# S3C2440A register map
Vendor: Samsung; Series: S3C2440; File version: 1.0
CPU: ARM920T r1p1, little endian, MPU, no FPU, 0 interrupt priority bits
Registers are 32-bit, read-write, reset 0x0 unless marked. A register's access mark holds for its fields unless they carry their own. Offsets are from the block's base; [hi:lo] are bit positions; {n}, {i} and the like mark numbered series.

## CLKPWR — Clock & Power Management
Base 0x4C000000
0x00 LOCKTIME reset 0xFFFFFF — PLL Lock Time Counter
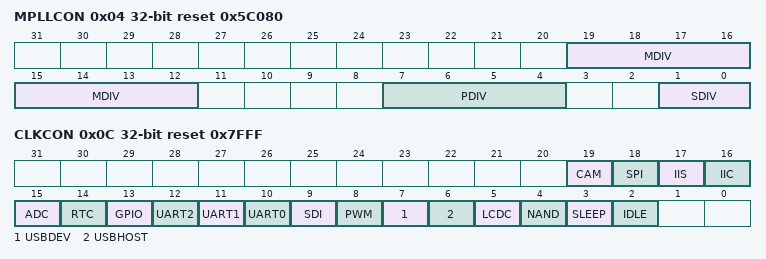
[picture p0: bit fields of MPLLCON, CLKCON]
0x04 MPLLCON reset 0x5C080 — MPLL Control Register
  [19:12] MDIV — Main Divider
  [7:4] PDIV — Pre-divider
  [1:0] SDIV — Post-divider
0x08 UPLLCON reset 0x28080 — UPLL Control Register
0x0C CLKCON reset 0x7FFF — Clock Control Register
  [19] CAM — Camera interface clock enable
  [18] SPI — SPI clock enable
  [17] IIS — IIS clock enable
  [16] IIC — IIC clock enable
  [15] ADC — ADC clock enable
  [14] RTC — RTC clock enable
  [13] GPIO — GPIO clock enable
  [12] UART2 — UART2 clock enable
  [11] UART1 — UART1 clock enable
  [10] UART0 — UART0 clock enable
  [9] SDI — SDI clock enable
  [8] PWM — PWM timer clock enable
  [7] USBDEV — USB device clock enable
  [6] USBHOST — USB host clock enable
  [5] LCDC — LCD controller clock enable
  [4] NAND — NAND Flash controller clock enable
  [3] SLEEP — Sleep mode
  [2] IDLE — Idle mode
0x10 CLKSLOW — Slow Clock Control Register
0x14 CLKDIVN — Clock Divider Control Register

## LCDC — LCD Controller
Base 0x4D000000
0x00 LCDCON1 — LCD Control 1 Register
0x04 LCDCON2 — LCD Control 2 Register
0x08 LCDCON3 — LCD Control 3 Register
0x0C LCDCON4 — LCD Control 4 Register
0x10 LCDCON5 — LCD Control 5 Register
0x14 LCDSADDR1 — Frame Buffer Start Address 1
0x18 LCDSADDR2 — Frame Buffer Start Address 2
0x1C LCDSADDR3 — Virtual Screen Address Set

## NFCON — NAND Flash Controller
Base 0x4E000000
0x00 NFCONF — NAND Flash Configuration
0x04 NFCMD 8-bit wo — NAND Flash Command
0x08 NFADDR 8-bit wo — NAND Flash Address
0x0C NFDATA 8-bit — NAND Flash Data
0x10 NFSTAT 8-bit ro — NAND Flash Status

## UART0
Base 0x50000000
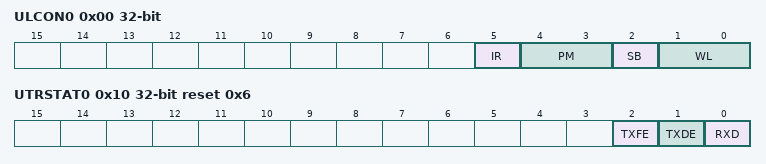
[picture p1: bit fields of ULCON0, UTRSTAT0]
0x00 ULCON0 — UART Line Control Register 0
  [5] IR — Infrared Mode (0=normal, 1=infrared)
  [4:3] PM — Parity Mode (00=no parity, 01=odd, 10=even, 11=parity forced/check)
  [2] SB — Stop Bits (0=1 bit, 1=2 bits)
  [1:0] WL — Word Length (00=5-bit, 01=6-bit, 10=7-bit, 11=8-bit)
0x04 UCON0 — UART Control Register 0
0x08 UFCON0 — UART FIFO Control Register 0
0x0C UMCON0 — UART Modem Control Register 0
0x10 UTRSTAT0 ro reset 0x6 — UART Tx/Rx Status Register 0
  [2] TXFE — Transmit FIFO empty (1=empty)
  [1] TXDE — Transmitter empty (1=empty)
  [0] RXD — Receive data ready (1=ready)
0x14 UERSTAT0 ro — UART Error Status Register 0
0x18 UFSTAT0 ro — UART FIFO Status Register 0
0x1C UMSTAT0 ro — UART Modem Status Register 0
0x20 UTXH0 8-bit wo — UART Transmission Hold Register 0
0x24 URXH0 8-bit ro — UART Receive Buffer Register 0
0x28 UBRDIV0 — Baud Rate Divisor Register 0

## PWM — PWM Timer
Base 0x51000000
0x00 TCFG0 — Timer Configuration 0
0x04 TCFG1 — Timer Configuration 1
0x08 TCON — Timer Control
0x0C TCNTB0 — Timer Count Buffer 0
0x10 TCMPB0 — Timer Compare Buffer 0
0x14 TCNTO0 ro — Timer Count Observation 0

## WDT — Watchdog Timer
Base 0x53000000
0x00 WTCON reset 0x8021 — Watchdog Timer Control Register
0x04 WTDAT reset 0x8000 — Watchdog Timer Data Register
0x08 WTCNT reset 0x8000 — Watchdog Timer Count Register

## I2C — I2C Controller
Base 0x54000000
0x00 IICCON — I2C Control
0x04 IICSTAT — I2C Status
0x08 IICADD — I2C Address
0x0C IICDS — I2C Data Shift

## GPIO — General Purpose I/O
Base 0x56000000
0x00 GPACON — Port A Control Register
0x04 GPADAT — Port A Data Register
0x10 GPBCON — Port B Control Register
0x14 GPBDAT — Port B Data Register
0x18 GPBUP — Port B Pull-up Disable Register
0x20 GPCCON — Port C Control Register
0x24 GPCDAT — Port C Data Register
0x28 GPCUP — Port C Pull-up Disable Register
0x30 GPDCON — Port D Control Register
0x34 GPDDAT — Port D Data Register
0x38 GPDUP — Port D Pull-up Disable Register
0x40 GPECON — Port E Control Register
0x44 GPEDAT — Port E Data Register
0x48 GPEUP — Port E Pull-up Disable Register
0x50 GPFCON — Port F Control Register
0x54 GPFDAT — Port F Data Register
0x58 GPFUP — Port F Pull-up Disable Register
0x60 GPGCON — Port G Control Register
0x64 GPGDAT — Port G Data Register
0x68 GPGUP — Port G Pull-up Disable Register
0x70 GPHCON — Port H Control Register
0x74 GPHDAT — Port H Data Register
0x78 GPHUP — Port H Pull-up Disable Register
{0x88+4i} EXTINT{i} (i=0..2) — External Interrupt Control Register {i}
0x94 EINTFLT0 — External Interrupt Filter Register 0
0x98 EINTFLT1 — External Interrupt Filter Register 1
0xA4 EINTMASK reset 0xFFFFF0 — External Interrupt Mask Register
0xA8 EINTPEND — External Interrupt Pending Register
0xAC GSTATUS0 ro reset 0x1 — External Pin Status Register 0
0xB0 GSTATUS1 ro — External Pin Status Register 1
{0xAC+4i} GSTATUS{i} (i=2..4) — External Pin Status Register {i}

## RTC — Real Time Clock
Base 0x57000000
0x00 RTCCON — RTC Control
0x08 TICNT — RTC Tick Time Count
0x10 RTCALM — RTC Alarm Control

## ADC — ADC and Touch Screen Interface
Base 0x58000000
0x00 ADCCON reset 0x20 — ADC Control
0x04 ADCTSC — ADC Touch Screen Control
0x08 ADCDLY reset 0xFF — ADC Start Delay
0x0C ADCDAT0 ro — ADC Conversion Data 0
0x10 ADCDAT1 ro — ADC Conversion Data 1

## SPI0
Base 0x59000000
0x00 SPCON0 — SPI Control Register 0
0x04 SPSTA0 ro — SPI Status Register 0
0x08 SPPIN0 — SPI Pin Control Register 0
0x0C SPPRE0 — SPI Baud Rate Prescaler Register 0
0x10 SPTDAT0 wo — SPI Tx Data Register 0
0x14 SPRDAT0 ro — SPI Rx Data Register 0

## SDI — SD Interface
Base 0x5A000000
0x00 SDICON — SDI Control
0x04 SDIPRE — SDI Baud Rate Prescaler
0x08 SDICmdArg wo — SDI Command Argument
0x0C SDICmdCon wo — SDI Command Control
0x10 SDICmdSta ro — SDI Command Status
{0x14+4i} SDIRSP{i} ro (i=0..3) — SDI Response {i}
0x24 SDIDTimer — SDI Data/Busy Timer
0x28 SDIBSize wo — SDI Block Size
0x2C SDIDatCon wo — SDI Data Control
0x30 SDIDatCnt wo — SDI Data Remain Counter
0x34 SDIDatSta ro — SDI Data Status
0x38 SDIFSTA ro — SDI FIFO Status
0x3C SDIDAT — SDI Data
